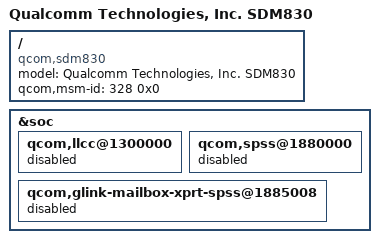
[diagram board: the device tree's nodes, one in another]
/* Copyright (c) 2016-2017, The Linux Foundation. All rights reserved.
 *
 * This program is free software; you can redistribute it and/or modify
 * it under the terms of the GNU General Public License version 2 and
 * only version 2 as published by the Free Software Foundation.
 *
 * This program is distributed in the hope that it will be useful,
 * but WITHOUT ANY WARRANTY; without even the implied warranty of
 * MERCHANTABILITY or FITNESS FOR A PARTICULAR PURPOSE.  See the
 * GNU General Public License for more details.
 */

/*
 * As a general rule, only version-specific property overrides should be placed
 * inside this file. Common device definitions should be placed inside the
 * sdm845.dtsi file.
 */

 #include "sdm845.dtsi"

/ {
	model = "Qualcomm Technologies, Inc. SDM830";
	compatible = "qcom,sdm830";
	qcom,msm-id = <328 0x0>;

};

&soc {
	qcom,llcc@1300000 {
		status = "disabled";
	};

	qcom,spss@1880000 {
		status = "disabled";
	};

	qcom,glink-mailbox-xprt-spss@1885008 {
		status = "disabled";
	};
};
